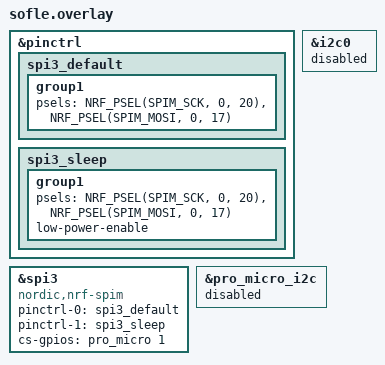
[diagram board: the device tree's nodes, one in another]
&pinctrl {
    spi3_default: spi3_default {
        group1 {
            psels = <NRF_PSEL(SPIM_SCK, 0, 20)>,
                <NRF_PSEL(SPIM_MOSI, 0, 17)>;
        };
    };

    spi3_sleep: spi3_sleep {
        group1 {
            psels = <NRF_PSEL(SPIM_SCK, 0, 20)>,
                <NRF_PSEL(SPIM_MOSI, 0, 17)>;
            low-power-enable;
        };
    };
};

nice_view_spi: &spi3 {
    compatible = "nordic,nrf-spim";
    pinctrl-0 = <&spi3_default>;
    pinctrl-1 = <&spi3_sleep>;
    pinctrl-names = "default", "sleep";
    cs-gpios = <&pro_micro 1 GPIO_ACTIVE_HIGH>;
};

// Disable I2C0 to avoid pin conflict if it's enabled elsewhere
&i2c0 {
    status = "disabled";
};

&pro_micro_i2c {
    status = "disabled";
};
